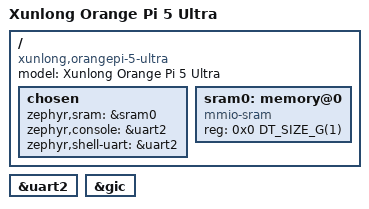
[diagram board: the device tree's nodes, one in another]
/*
 * SPDX-License-Identifier: Apache-2.0
 * Copyright The Zephyr Project Contributors
 */

/dts-v1/;

#include <rockchip/rk3588.dtsi>
#include <common/mem.h>

/ {
	compatible = "xunlong,orangepi-5-ultra", "rockchip,rk3588";
	model = "Xunlong Orange Pi 5 Ultra";

	chosen {
		zephyr,sram = &sram0;
		zephyr,console = &uart2;
		zephyr,shell-uart = &uart2;
	};

	sram0: memory@0 {
		compatible = "mmio-sram";
		reg = <0x0 DT_SIZE_G(1)>;
		device_type = "memory";
	};
};

&uart2 {
	status = "okay";
};

&gic {
	status = "okay";
};
